# R5SS_VIM0_50F00000h register map
Vendor: Texas Instruments
Peripheral module from a debugger description file (folder AM263P).
Registers are 32-bit, read-only, reset 0x0 unless marked. A register's access mark holds for its fields unless they carry their own. Offsets are as the file gives them; lines under a group give offsets from that group; [hi:lo] are bit positions; {n}, {i} and the like mark numbered series; 'fields as' and 'values as' point back to an identical list; <NAME> marks a mode.

## VIM0
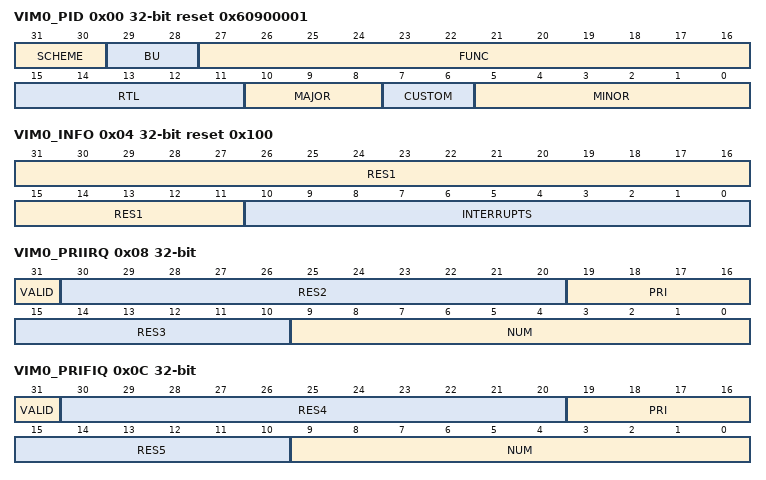
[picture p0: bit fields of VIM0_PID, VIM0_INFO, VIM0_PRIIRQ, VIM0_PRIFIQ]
0x00 VIM0_PID reset 0x60900001 — The Revision Register contains the major and minor revisions for the module.
  [31:30] SCHEME — PID register scheme
  [29:28] BU — Business Unit: 10 = Processors
  [27:16] FUNC — Module ID
  [15:11] RTL — RTL revision. Will vary depending on release.
  [10:8] MAJOR — Major revision
  [7:6] CUSTOM
  [5:0] MINOR — Minor revision
0x04 VIM0_INFO reset 0x100 — The Info Register gives the configuration Inforrmation of this VIM.
  [31:11] RES1 — RESERVE FIELD
  [10:0] INTERRUPTS — Total number of Interrupts
0x08 VIM0_PRIIRQ — The Prioritized IRQ Register shows the number of the highest priority pending IRQ.
  [31] VALID — Indicates that the num field is valid.
  [30:20] RES2 — RESERVE FIELD
  [19:16] PRI — Priority of the highest priority pending IRQ. valid only if the valid flag is set.
  [15:10] RES3 — RESERVE FIELD
  [9:0] NUM — Number of the highest priority pending IRQ. valid only if the valid flag is set.
0x0C VIM0_PRIFIQ — The Prioritized FIQ Register shows the number of the highest priority pending FIQ.
  [31] VALID — Indicates that the num field is valid.
  [30:20] RES4 — RESERVE FIELD
  [19:16] PRI — Priority of the highest priority pending FIQ. valid only if the valid flag is set.
  [15:10] RES5 — RESERVE FIELD
  [9:0] NUM — Number of the highest priority pending FIQ. valid only if the valid flag is set.
0x10 VIM0_IRQGSTS — The IRQ Group Status Register indicates which groups have pending IRQ interrupts.
  [31:0] STS — Indicates that the num field is valid. This field indicates that one or more interrupts in Group M are mapped to IRQ, unmasked, and pending. Bit 0 corresponds to Group 0; Bit 1 corresponds to Group 1 etc. The interrupts associated with each group are [(M*32)+31:M*32].
0x14 VIM0_FIQGSTS — The FIQ Group Status Register indicates which groups have pending FIQ interrupts.
  [31:0] STS — Indicates that the num field is valid. This field indicates that one or more interrupts in Group M are mapped to FIQ, unmasked, and pending. Bit 0 corresponds to Group 0; Bit 1 corresponds to Group 1 etc. The interrupts associated with each group are [(M*32)+31:M*32].
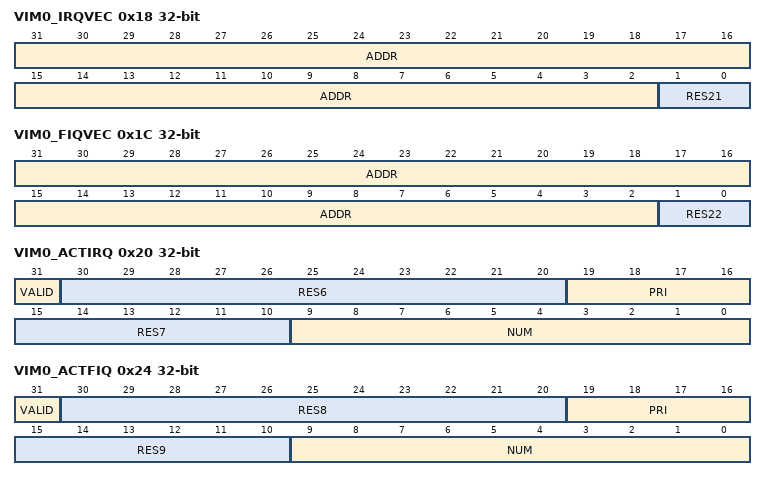
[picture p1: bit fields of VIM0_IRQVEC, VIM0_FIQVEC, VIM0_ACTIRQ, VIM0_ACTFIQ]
0x18 VIM0_IRQVEC access per field — The IRQ Vector Address Register contains the 32-bit address of the interrupt vector for the current pendind IRQ.
  [31:2] ADDR rw — Upper 30 bits of the 32-bit vector address. Only valid if the Prioritized IRQ Register valid flag is true.
  [1:0] RES21 ro — RESERVE FIELD
0x1C VIM0_FIQVEC access per field — The FIQ Vector Address Register contains the 32-bit address of the interrupt vector for the current pendind FIQ.
  [31:2] ADDR rw — Upper 30 bits of the 32-bit vector address. Only valid if the Prioritized FIQ Register valid flag is true.
  [1:0] RES22 ro — RESERVE FIELD
0x20 VIM0_ACTIRQ — The Active IRQ Register shows the number of the currently active IRQ.
  [31] VALID — Indicates that the num field is valid. Set when the IRQ Vector Address Register is read and cleared whenever the IRQ Vector Address Register is written.
  [30:20] RES6 — RESERVE FIELD
  [19:16] PRI — Priority of the highest priority pending IRQ. valid only if the valid flag is set.
  [15:10] RES7 — RESERVE FIELD
  [9:0] NUM — Number of the currently active IRQ. Loaded from teh Prioritized IRQ Register whenever the IRQ Vector Address is read. Valid only if the valid flag is set.
0x24 VIM0_ACTFIQ — The Active FIQ Register shows the number of the currently active FIQ.
  [31] VALID — Indicates that the num field is valid. Set when the FIQ Vector Address Register is read and cleared whenever the FIQ Vector Address Register is written.
  [30:20] RES8 — RESERVE FIELD
  [19:16] PRI — Priority of the highest priority pending IRQ. valid only if the valid flag is set.
  [15:10] RES9 — RESERVE FIELD
  [9:0] NUM — Number of the currently active FIQ. Loaded from teh Prioritized FIQ Register whenever the FIQ Vector Address is read. Valid only if the valid flag is set.
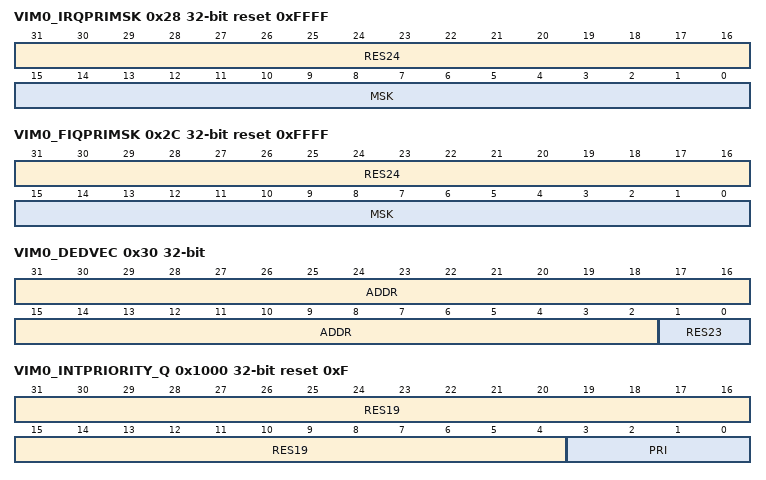
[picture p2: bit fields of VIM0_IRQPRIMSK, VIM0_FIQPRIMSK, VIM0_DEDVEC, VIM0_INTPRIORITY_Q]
0x28 VIM0_IRQPRIMSK access per field reset 0xFFFF — The IRQ Priority Mask Register allows all IRQs of a particular priority to be enabled or disabled.
  [31:16] RES24 ro — RESERVE FIELD
  [15:0] MSK rw — Each bit corresponds to the given priority. 1 - IRQs of this priority are enabled. 0 - IRQs of this priority are disabled.
0x2C VIM0_FIQPRIMSK access per field reset 0xFFFF — The FIQ Priority Mask Register allows all FIQs of a particular priority to be enabled or disabled.
  [31:16] RES24 ro — RESERVE FIELD
  [15:0] MSK rw — Each bit corresponds to the given priority. 1 - FIQs of this priority are enabled. 0 - FIQs of this priority are disabled.
0x30 VIM0_DEDVEC access per field — The DED Vector Address contains a default vector address for when an uncorrectable error is detected for an active IRQ or FIQ.
  [31:2] ADDR rw — Upper 30 bits of the 32-bit vector address.
  [1:0] RES23 ro — RESERVE FIELD
0x400 VIM0_RAW_M rw — Group M Interrupt Raw Status/Set Register (M is 0 to 7) Address formula = 50F00000h + Offset + M x 20h.
  [31:0] STS — This is the raw status of the events in Group M Each bit corresponds to event Q where Q = Mx32+Bit Read 0 InactiveRead 1 Active/PendingWrite 0 No effectWrite 1 Set to Interrupt Raw Status
0x404 VIM0_STS_M rw — Group M Interrupt Enabled Status/Clear Register (M is 0 to 7) Address formula = 50F00000h + Offset + M x 20h .
  [31:0] MASK — This is the masked status of the events in Group M Each bit corresponds to event Q where Q = Mx32+Bit Read 0 Inactive or DisabledRead 1 Active/Pending and EnabledWrite 0 No effectWrite 1 Clear Interrupt Raw Status
0x408 VIM0_INTR_EN_SET_M rw — Group M Interrupt Enabled Set Register (M is 0 to 7) Address formula = 50F00000h + Offset + M x 20h.
  [31:0] MASK — This field is used to enable the mask of events in Group M Each bit corresponds to event Q where Q = Mx32+BitRead 0 DisabledRead 1 EnabledWrite 0 No effectWrite 1 Set Enable
0x40C VIM0_INTER_EN_CLR_M rw — Group M Interrupt Enabled Clear Register (M is 0 to 7)Address formula = 50F00000h + Offset + M x 20h.
  [31:0] MASK — This field is used to disable the mask of events in Group M Each bit corresponds to event Q where Q = Mx32+BitRead 0 DisabledRead 1 EnabledWrite 0 No effectWrite 1 Clear Enable
0x410 VIM0_IRQSTS_M rw — Group M Interrupt IRQ Enabled Status/Clear Register (M is 0 to 7) Address formula = 50F00000h + Offset + M x 20h.
  [31:0] MASK — This is the masked status of the events in group M that are mapped to IRQ Each bit corresponds to event Q where Q = Mx32+BitRead 0 Inactive, Disabled, or not an IRQRead 1 Active/Pending, Enabled, and IRQWrite 0 No effectWrite 1 Clear Interrupt Raw Status [if IRQ]
0x414 VIM0_FIQSTS_M rw — Group M Interrupt FIQ Enabled Status/Clear Register (M is 0 to 7) Address formula = 50F00000h + Offset + M x 20h.
  [31:0] MASK — This is the masked status of the events in group M that are mapped to FIQ Each bit corresponds to event Q where Q = Mx32+BitRead 0 Inactive, Disabled, or not an FIQRead 1 Active/Pending, Enabled, and FIQWrite 0 No effectWrite 1 Clear Interrupt Raw Status [if FIQ]
0x418 VIM0_INTMAP_M rw — Group M Interrupt Map Register (M is 0 to 7) Address formula = 50F00000h + Offset + M x 20h.
  [31:0] MASK — This field is used to indicate which interrupt the corresponding event influences [if enabled] for event group M. Each bit corresponds to event Q where Q = Mx32+Bit 0 IRQ Interrupt [default]1 FIQ Interrupt
0x41C VIM0_INTTYPE_M rw — Group M Interrupt Type Map Register (M is 0 to 7) Address formula = 50F00000h + Offset + M x 20h.
  [31:0] VAL — This field is used to indicate whether the source of an interrupt is a level [default] or a pulse for event group M. This is informational so that an ISR may query this register and know whether it has to clear a pulse event or a level event [see 3.4 Interrupt Handling]. The value has no effect on how the VIM hardware functions. The input interrupts are agnostic as to whether they are pulse or level. Each bit corresponds to event Q where Q = Mx32+Bit0 Level [default]1 Pulse
0x1000 VIM0_INTPRIORITY_Q access per field reset 0xF — Interrupt Q Priority Register (where Q is 0 to 255) Address formula = 50F00000h + Offset + Q x 4h.
  [31:4] RES19 ro — RESERVE FIELD
  [3:0] PRI rw — This is the priority for interrupt Q. If two interrupts have the same priority, then whichever interrupt has the lower number Q wins arbitration 0 Highest Priority 15 Lowest Priority [Default]
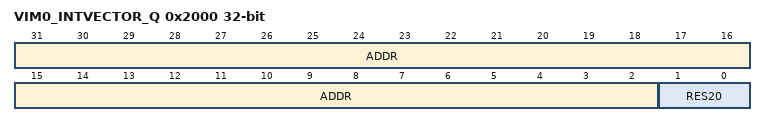
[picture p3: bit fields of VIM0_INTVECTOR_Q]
0x2000 VIM0_INTVECTOR_Q access per field — Interrupt Q Vector Register (Q is 0 to 255) Address formula = 50F00000h + Offset + Q x 4h.
  [31:2] ADDR rw — This is the 32-bit Vector Address associated with interrupt Q. It is the address that will be reflected in the IRQ Vector Address [Base Address + 0x18] or FIQ Vector Address [Base Address + 0x1C] and the VECADDR pin when interrupt Q is the active interrupt.Internally, these values are kept in a RAM. The FIQ and IRQ state machines have priority access to this RAM. Writes to this register will be piped internally, but further writes to the MMR interface may be stalled until this write has a chance to complete in the RAM. The new Vector Address will not take effect until this write completes to the RAM. In order to tell if this write has completed, software may read this register back. That read will not be able to complete unless the write has landed.Reads to this register will stall the MMR interface until the read is able to be completed at the RAM.
  [1:0] RES20 ro — Reserved. Read as 0. The lower 2 bits of the 32-bit vector address are always 0. Vector addresses must be 32-bit aligned.
